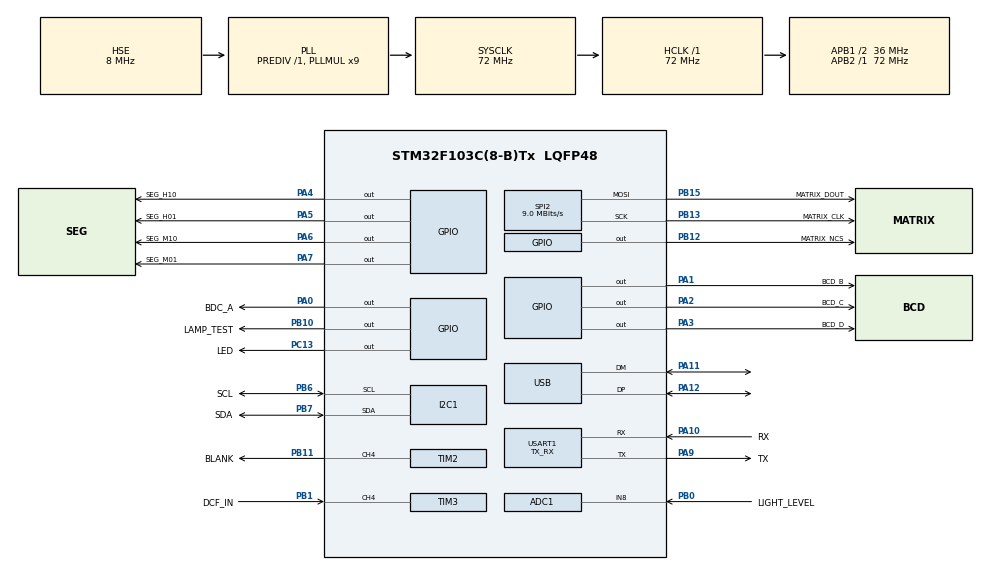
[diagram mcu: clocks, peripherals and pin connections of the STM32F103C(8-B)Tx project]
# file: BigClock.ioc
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Mcu.Family=STM32F1
Dma.SPI2_TX.0.MemInc=DMA_MINC_ENABLE
USB_DEVICE.CLASS_NAME_FS=CDC
NVIC.DMA1_Channel5_IRQn=true\:5\:0\:false\:false\:true\:true\:false\:true
SPI2.VirtualType=VM_MASTER
PA14.GPIO_Label=SWCLK
PA11.Mode=Device
VP_TIM3_VS_no_output2.Mode=Output Compare2 No Output
PA6.GPIO_Label=SEG_M10
PB0.GPIO_Label=LIGHT_LEVEL
PB6.GPIO_Label=SCL
NVIC.TIM1_UP_IRQn=true\:0\:0\:false\:false\:true\:false\:false\:true
PB13.GPIO_Label=MATRIX_CLK
PB11.Signal=S_TIM2_CH4
PB13.Signal=SPI2_SCK
PB15.Signal=SPI2_MOSI
PC15-OSC32_OUT.GPIO_Label=OSC32_OUT
Dma.SPI2_TX.0.Instance=DMA1_Channel5
RCC.SYSCLKSource=RCC_SYSCLKSOURCE_PLLCLK
ProjectManager.StackSize=0x400
VP_FREERTOS_VS_CMSIS_V2.Mode=CMSIS_V2
PD1-OSC_OUT.Signal=RCC_OSC_OUT
Dma.SPI2_TX.0.MemDataAlignment=DMA_MDATAALIGN_HALFWORD
TIM3.Channel-Input_Capture3_from_TI4=TIM_CHANNEL_3
PD1-OSC_OUT.GPIO_Label=OSC_OUT
PA12.Signal=USB_DP
PB1.GPIO_PuPd=GPIO_PULLUP
RCC.HCLKFreq_Value=72000000
RCC.APB2TimFreq_Value=72000000
TIM3.Period=1125
PB6.Signal=I2C1_SCL
PB6.Mode=I2C
TIM3.Pulse-Output\ Compare1\ No\ Output=562
Dma.SPI2_TX.0.Mode=DMA_NORMAL
RCC.AHBFreq_Value=72000000
SPI2.BaudRatePrescaler=SPI_BAUDRATEPRESCALER_4
FREERTOS.configUSE_PREEMPTION=0
TIM3.ClockDivision=TIM_CLOCKDIVISION_DIV1
ADC1.Channel-0\#ChannelRegularConversion=ADC_CHANNEL_8
PB3.Mode=Trace_Asynchronous_SW
RCC.RTCClockSelection=RCC_RTCCLKSOURCE_LSE
RCC.PLLMUL=RCC_PLL_MUL9
PB12.GPIO_Label=MATRIX_NCS
PA14.Mode=Trace_Asynchronous_SW
VP_SYS_VS_tim1.Mode=TIM1
TIM3.Prescaler=63946
PB1.GPIO_Label=DCF_IN
PA10.GPIO_Label=RX
SH.ADCx_IN8.0=ADC1_IN8,IN8
SPI2.CalculateBaudRate=9.0 MBits/s
PB7.Signal=I2C1_SDA
ADC1.SamplingTime-0\#ChannelRegularConversion=ADC_SAMPLETIME_1CYCLE_5
PB7.GPIO_Label=SDA
Mcu.Package=LQFP48
PB1.Signal=S_TIM3_CH4
PA6.Signal=GPIO_Output
NVIC.TimeBase=TIM1_UP_IRQn
SPI2.Mode=SPI_MODE_MASTER
PA2.GPIO_Label=BCD_C
NVIC.TimeBaseIP=TIM1
PA10.Signal=USART1_RX
Dma.SPI2_TX.0.PeriphInc=DMA_PINC_DISABLE
RCC.APB1TimFreq_Value=72000000
PC14-OSC32_IN.GPIO_Label=OSC32_IN
SPI2.Direction=SPI_DIRECTION_2LINES
PB13.Mode=TX_Only_Simplex_Unidirect_Master
Dma.Request0=SPI2_TX
PA4.GPIO_Label=SEG_H10
VP_TIM3_VS_ClockSourceINT.Mode=Internal
PA3.Signal=GPIO_Output
PB3.GPIO_Label=SWO
RCC.PLLSourceVirtual=RCC_PLLSOURCE_HSE
TIM2.Channel-PWM\ Generation4\ CH4=TIM_CHANNEL_4
FREERTOS.Tasks01=dcfTimerTask,48,128,dcfTimerFunc,As weak,NULL,Static,dcfTimerTaskBuffer,dcfTimerTaskControlBlock;matrixTask,24,256,matrixTaskFun,As external,NULL,Static,matrixTaskBuffer,matrixTaskControlBlock
ADC1.Rank-0\#ChannelRegularConversion=1
TIM3.Channel-Output\ Compare1\ No\ Output=TIM_CHANNEL_1
PD1-OSC_OUT.Mode=HSE-External-Oscillator
PA10.Mode=Asynchronous
TIM3.AutoReloadPreload=TIM_AUTORELOAD_PRELOAD_ENABLE
USB_DEVICE.VirtualModeFS=Cdc_FS
PA9.GPIO_Label=TX
PB11.GPIO_Label=BLANK
PC13-TAMPER-RTC.Signal=GPIO_Output
RCC.USBPrescaler=RCC_USBCLKSOURCE_PLL_DIV1_5
PD0-OSC_IN.Signal=RCC_OSC_IN
RCC.APB1CLKDivider=RCC_HCLK_DIV2
PC14-OSC32_IN.Signal=RCC_OSC32_IN
PA0-WKUP.GPIO_Label=BDC_A
PA0-WKUP.Signal=GPIO_Output
RCC.ADCPresc=RCC_ADCPCLK2_DIV6
PA13.Signal=SYS_JTMS-SWDIO
PA9.Mode=Asynchronous
ProjectManager.TargetToolchain=STM32CubeIDE
PB10.GPIO_Label=LAMP_TEST
VP_USB_DEVICE_VS_USB_DEVICE_CDC_FS.Mode=CDC_FS
PA9.Signal=USART1_TX
RCC.USBFreq_Value=48000000
PC15-OSC32_OUT.Signal=RCC_OSC32_OUT
PA1.Signal=GPIO_Output
PD0-OSC_IN.Mode=HSE-External-Oscillator
PB10.Signal=GPIO_Output
PA5.Signal=GPIO_Output
board=custom
PD0-OSC_IN.GPIO_Label=OSC_IN
VP_TIM3_VS_no_output1.Mode=Output Compare1 No Output
PC13-TAMPER-RTC.GPIO_Label=LED
PB15.Mode=TX_Only_Simplex_Unidirect_Master
NVIC.TIM3_IRQn=true\:5\:0\:false\:false\:true\:true\:true\:true
RCC.APB2Freq_Value=72000000
USART1.Mode=MODE_TX_RX
PB15.GPIO_Label=MATRIX_DOUT
VP_TIM2_VS_ClockSourceINT.Mode=Internal
TIM3.Pulse-Output\ Compare2\ No\ Output=619
Dma.SPI2_TX.0.PeriphDataAlignment=DMA_PDATAALIGN_HALFWORD
NVIC.USB_LP_CAN1_RX0_IRQn=true\:5\:0\:false\:false\:true\:true\:false\:true
PA1.GPIO_Label=BCD_B
TIM3.ICPolarity_CH4=TIM_INPUTCHANNELPOLARITY_FALLING
TIM3.ICPolarity_CH3=TIM_INPUTCHANNELPOLARITY_RISING
TIM3.Channel-Input_Capture4_from_TI4=TIM_CHANNEL_4
TIM2.Period=0xffff
PA13.Mode=Trace_Asynchronous_SW
Mcu.Name=STM32F103C(8-B)Tx
PA2.Signal=GPIO_Output
PA13.GPIO_Label=SWDIO
PB3.Signal=SYS_JTDO-TRACESWO
PA4.Signal=GPIO_Output
Dma.SPI2_TX.0.Priority=DMA_PRIORITY_LOW
RCC.SYSCLKFreq_VALUE=72000000
PA7.GPIO_Label=SEG_M01
ADC1.master=1
PA12.Mode=Device
PA5.GPIO_Label=SEG_H01
USART1.VirtualMode=VM_ASYNC
TIM3.Channel-Output\ Compare2\ No\ Output=TIM_CHANNEL_2
PA11.Signal=USB_DM
PB7.Mode=I2C
PA14.Signal=SYS_JTCK-SWCLK
ProjectManager.HeapSize=0x200
SH.S_TIM2_CH4.0=TIM2_CH4,PWM Generation4 CH4
NVIC.PriorityGroup=NVIC_PRIORITYGROUP_4
ADC1.NbrOfConversionFlag=1
TIM2.Pulse-PWM\ Generation4\ CH4=65535
SPI2.DataSize=SPI_DATASIZE_16BIT
TIM3.TIM_MasterOutputTrigger=TIM_TRGO_RESET
Dma.SPI2_TX.0.Direction=DMA_MEMORY_TO_PERIPH
RCC.APB1Freq_Value=36000000
PB0.Signal=ADCx_IN8
USB_DEVICE.VirtualMode=Cdc
PB12.Signal=GPIO_Output
SH.S_TIM3_CH4.1=TIM3_CH4,Input_Capture3_from_TI4
PA3.GPIO_Label=BCD_D
SH.S_TIM3_CH4.0=TIM3_CH4,Input_Capture4_from_TI4
PA7.Signal=GPIO_Output

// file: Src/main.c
/* USER CODE BEGIN Header */
/**
  ******************************************************************************
  * @file           : main.c
  * @brief          : Main program body
  ******************************************************************************
  * @attention
  *
  * <h2><center>&copy; Copyright (c) 2020 STMicroelectronics.
  * All rights reserved.</center></h2>
  *
  * This software component is licensed by ST under Ultimate Liberty license
  * SLA0044, the "License"; You may not use this file except in compliance with
  * the License. You may obtain a copy of the License at:
  *                             www.st.com/SLA0044
  *
  ******************************************************************************
  */
/* USER CODE END Header */
#include "main.h"
#include "cmsis_os.h"
#include "adc.h"
#include "dma.h"
#include "i2c.h"
#include "spi.h"
#include "tim.h"
#include "usart.h"
#include "usb_device.h"
#include "gpio.h"

/* USER CODE BEGIN Includes */
#include "main2.hpp"
/* USER CODE END Includes */

void SystemClock_Config(void);
void MX_FREERTOS_Init(void);

int main(void)
{

  /* MCU Configuration--------------------------------------------------------*/

  /* Reset of all peripherals, Initializes the Flash interface and the Systick. */
  HAL_Init();

  /* Configure the system clock */
  SystemClock_Config();

  /* Initialize all configured peripherals */
  MX_GPIO_Init();
  MX_DMA_Init();
  MX_TIM3_Init();
  MX_ADC1_Init();
  MX_I2C1_Init();
  MX_USART1_UART_Init();
  MX_TIM2_Init();
  MX_SPI2_Init();

  /* Init scheduler */
  osKernelInitialize();  /* Call init function for freertos objects (in freertos.c) */
  MX_FREERTOS_Init();
  /* Start scheduler */
  osKernelStart();

  /* We should never get here as control is now taken by the scheduler */
  /* Infinite loop */
  while (1)
  {

  }
}

void SystemClock_Config(void)
{
  RCC_OscInitTypeDef RCC_OscInitStruct = {0};
  RCC_ClkInitTypeDef RCC_ClkInitStruct = {0};
  RCC_PeriphCLKInitTypeDef PeriphClkInit = {0};

  /** Initializes the RCC Oscillators according to the specified parameters
  * in the RCC_OscInitTypeDef structure.
  */
  RCC_OscInitStruct.OscillatorType = RCC_OSCILLATORTYPE_HSE;
  RCC_OscInitStruct.HSEState = RCC_HSE_ON;
  RCC_OscInitStruct.HSEPredivValue = RCC_HSE_PREDIV_DIV1;
  RCC_OscInitStruct.HSIState = RCC_HSI_ON;
  RCC_OscInitStruct.PLL.PLLState = RCC_PLL_ON;
  RCC_OscInitStruct.PLL.PLLSource = RCC_PLLSOURCE_HSE;
  RCC_OscInitStruct.PLL.PLLMUL = RCC_PLL_MUL9;
  if (HAL_RCC_OscConfig(&RCC_OscInitStruct) != HAL_OK)
  {
    Error_Handler();
  }
  /** Initializes the CPU, AHB and APB buses clocks
  */
  RCC_ClkInitStruct.ClockType = RCC_CLOCKTYPE_HCLK|RCC_CLOCKTYPE_SYSCLK
                              |RCC_CLOCKTYPE_PCLK1|RCC_CLOCKTYPE_PCLK2;
  RCC_ClkInitStruct.SYSCLKSource = RCC_SYSCLKSOURCE_PLLCLK;
  RCC_ClkInitStruct.AHBCLKDivider = RCC_SYSCLK_DIV1;
  RCC_ClkInitStruct.APB1CLKDivider = RCC_HCLK_DIV2;
  RCC_ClkInitStruct.APB2CLKDivider = RCC_HCLK_DIV1;

  if (HAL_RCC_ClockConfig(&RCC_ClkInitStruct, FLASH_LATENCY_2) != HAL_OK)
  {
    Error_Handler();
  }
  PeriphClkInit.PeriphClockSelection = RCC_PERIPHCLK_ADC|RCC_PERIPHCLK_USB;
  PeriphClkInit.AdcClockSelection = RCC_ADCPCLK2_DIV6;
  PeriphClkInit.UsbClockSelection = RCC_USBCLKSOURCE_PLL_DIV1_5;
  if (HAL_RCCEx_PeriphCLKConfig(&PeriphClkInit) != HAL_OK)
  {
    Error_Handler();
  }
}

 /**
  * @brief  Period elapsed callback in non blocking mode
  * @note   This function is called  when TIM1 interrupt took place, inside
  * HAL_TIM_IRQHandler(). It makes a direct call to HAL_IncTick() to increment
  * a global variable "uwTick" used as application time base.
  * @param  htim : TIM handle
  * @retval None
  */
void HAL_TIM_PeriodElapsedCallback(TIM_HandleTypeDef *htim)
{
  if (htim->Instance == TIM1) {
    HAL_IncTick();
  }
  /* USER CODE BEGIN Callback 1 */
  else if (htim->Instance == TIM3) {
    HAL_TIM3_PeriodElapsedCallback();
  }
  /* USER CODE END Callback 1 */
}

void Error_Handler(void)
{
}

/************************ (C) COPYRIGHT STMicroelectronics *****END OF FILE****/

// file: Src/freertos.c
/* USER CODE BEGIN Header */
/**
  ******************************************************************************
  * File Name          : freertos.c
  * Description        : Code for freertos applications
  ******************************************************************************
  * @attention
  *
  * <h2><center>&copy; Copyright (c) 2020 STMicroelectronics.
  * All rights reserved.</center></h2>
  *
  * This software component is licensed by ST under Ultimate Liberty license
  * SLA0044, the "License"; You may not use this file except in compliance with
  * the License. You may obtain a copy of the License at:
  *                             www.st.com/SLA0044
  *
  ******************************************************************************
  */
/* USER CODE END Header */

#include "FreeRTOS.h"
#include "task.h"
#include "main.h"
#include "cmsis_os.h"

/* USER CODE BEGIN Includes */
#include "dcf_timer.hpp"
#include "matrix.hpp"
#include "main2.hpp"
/* USER CODE END Includes */

typedef StaticTask_t osStaticThreadDef_t;

/* Definitions for dcfTimerTask */
osThreadId_t dcfTimerTaskHandle;
uint32_t dcfTimerTaskBuffer[ 128 ];
osStaticThreadDef_t dcfTimerTaskControlBlock;
const osThreadAttr_t dcfTimerTask_attributes = {
  .name = "dcfTimerTask",
  .cb_mem = &dcfTimerTaskControlBlock,
  .cb_size = sizeof(dcfTimerTaskControlBlock),
  .stack_mem = &dcfTimerTaskBuffer[0],
  .stack_size = sizeof(dcfTimerTaskBuffer),
  .priority = (osPriority_t) osPriorityRealtime,
};
/* Definitions for matrixTask */
osThreadId_t matrixTaskHandle;
uint32_t matrixTaskBuffer[ 256 ];
osStaticThreadDef_t matrixTaskControlBlock;
const osThreadAttr_t matrixTask_attributes = {
  .name = "matrixTask",
  .cb_mem = &matrixTaskControlBlock,
  .cb_size = sizeof(matrixTaskControlBlock),
  .stack_mem = &matrixTaskBuffer[0],
  .stack_size = sizeof(matrixTaskBuffer),
  .priority = (osPriority_t) osPriorityNormal,
};

void dcfTimerFunc(void *argument);
extern void matrixTaskFun(void *argument);

extern void MX_USB_DEVICE_Init(void);
void MX_FREERTOS_Init(void); /* (MISRA C 2004 rule 8.1) */

void MX_FREERTOS_Init(void) {

  /* Create the thread(s) */
  /* creation of dcfTimerTask */
  dcfTimerTaskHandle = osThreadNew(dcfTimerFunc, NULL, &dcfTimerTask_attributes);

  /* creation of matrixTask */
  matrixTaskHandle = osThreadNew(matrixTaskFun, NULL, &matrixTask_attributes);

}

__weak void dcfTimerFunc(void *argument)
{
  /* init code for USB_DEVICE */
  MX_USB_DEVICE_Init();
  for(;;)
  {
    osDelay(1);
  }
}

/************************ (C) COPYRIGHT STMicroelectronics *****END OF FILE****/
